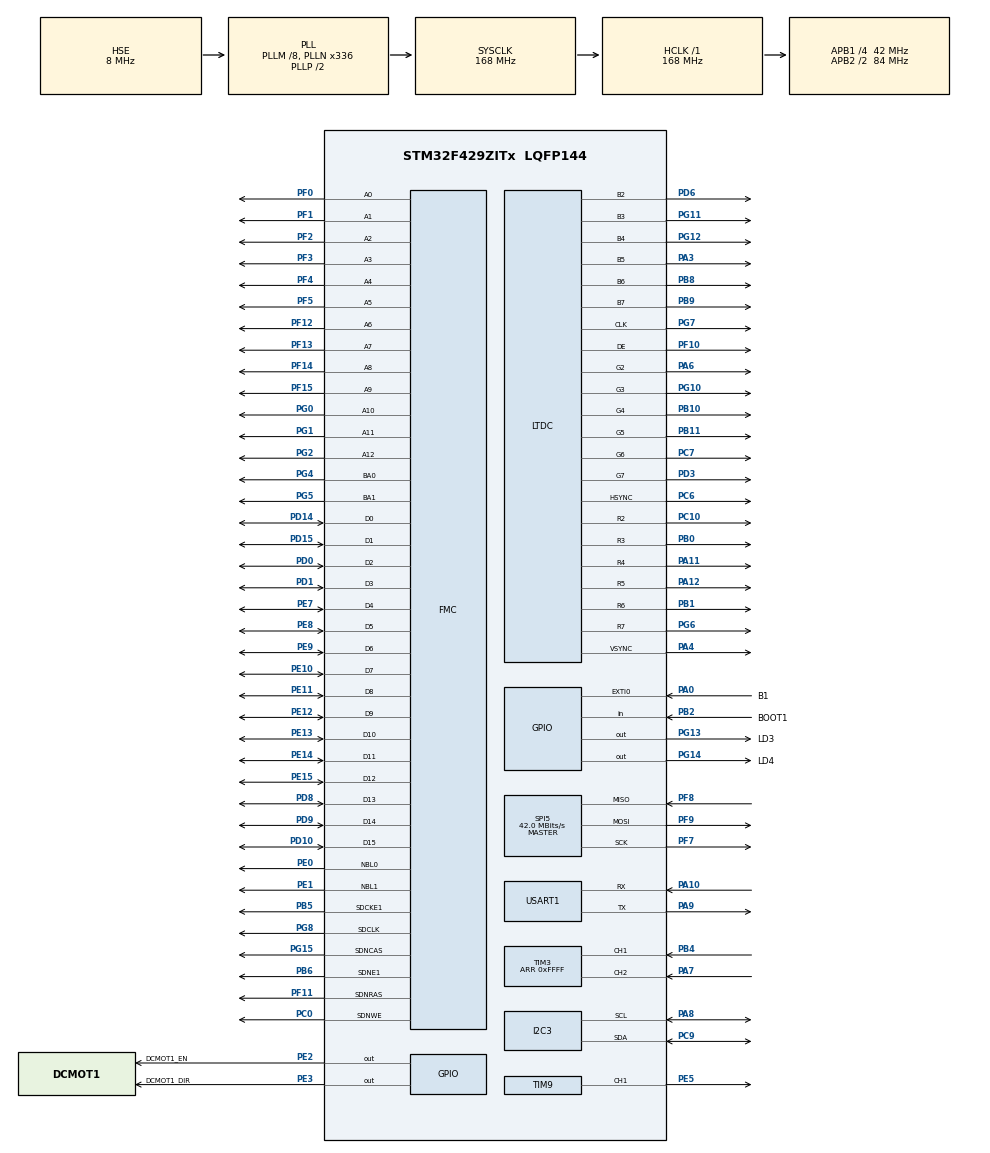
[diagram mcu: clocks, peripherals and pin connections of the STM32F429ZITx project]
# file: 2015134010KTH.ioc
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DMA2D.ColorMode=DMA2D_OUTPUT_RGB565
LTDC.ActiveH=240
LTDC.ActiveW=320
Mcu.Family=STM32F4
Mcu.Name=STM32F429ZITx
Mcu.Package=LQFP144
NVIC.EXTI0_IRQn=true\:0\:0\:false\:true\:true\:1\:true\:true
NVIC.PriorityGroup=NVIC_PRIORITYGROUP_4
NVIC.TIM6_DAC_IRQn=true\:0\:0\:false\:true\:true\:2\:true\:true
PA0/WKUP.GPIO_Label=B1
PA0/WKUP.Signal=GPXTI0
PA10.Mode=Asynchronous
PA10.Signal=USART1_RX
PA11.Mode=RGB666
PA11.Signal=LTDC_R4
PA12.Mode=RGB666
PA12.Signal=LTDC_R5
PA13.Mode=Serial_Wire
PA13.Signal=SYS_JTMS-SWDIO
PA14.Mode=Serial_Wire
PA14.Signal=SYS_JTCK-SWCLK
PA3.Mode=RGB666
PA3.Signal=LTDC_B5
PA4.Mode=RGB666
PA4.Signal=LTDC_VSYNC
PA6.Mode=RGB666
PA6.Signal=LTDC_G2
PA7.GPIO_Speed=GPIO_SPEED_FREQ_VERY_HIGH
PA7.Signal=S_TIM3_CH2
PA8.Mode=I2C
PA8.Signal=I2C3_SCL
PA9.Mode=Asynchronous
PA9.Signal=USART1_TX
PB0.Mode=RGB666
PB0.Signal=LTDC_R3
PB1.Mode=RGB666
PB1.Signal=LTDC_R6
PB10.Mode=RGB666
PB10.Signal=LTDC_G4
PB11.Mode=RGB666
PB11.Signal=LTDC_G5
PB2/BOOT1.GPIO_Label=BOOT1
PB2/BOOT1.Signal=GPIO_Input
PB4.GPIO_Speed=GPIO_SPEED_FREQ_VERY_HIGH
PB4.Signal=S_TIM3_CH1
PB5.Mode=SdramChipSelect2_1
PB5.Signal=FMC_SDCKE1
PB6.Mode=SdramChipSelect2_1
PB6.Signal=FMC_SDNE1
PB8.Mode=RGB666
PB8.Signal=LTDC_B6
PB9.Mode=RGB666
PB9.Signal=LTDC_B7
PC0.Signal=FMC_SDNWE
PC10.Mode=RGB666
PC10.Signal=LTDC_R2
PC6.Mode=RGB666
PC6.Signal=LTDC_HSYNC
PC7.Mode=RGB666
PC7.Signal=LTDC_G6
PC9.Mode=I2C
PC9.Signal=I2C3_SDA
PD0.Signal=FMC_D2_DA2
PD1.Signal=FMC_D3_DA3
PD10.Signal=FMC_D15_DA15
PD14.Signal=FMC_D0_DA0
PD15.Signal=FMC_D1_DA1
PD3.Mode=RGB666
PD3.Signal=LTDC_G7
PD6.Mode=RGB666
PD6.Signal=LTDC_B2
PD8.Signal=FMC_D13_DA13
PD9.Signal=FMC_D14_DA14
PE0.Signal=FMC_NBL0
PE1.Signal=FMC_NBL1
PE10.Signal=FMC_D7_DA7
PE11.Signal=FMC_D8_DA8
PE12.Signal=FMC_D9_DA9
PE13.Signal=FMC_D10_DA10
PE14.Signal=FMC_D11_DA11
PE15.Signal=FMC_D12_DA12
PE2.GPIO_Label=DCMOT1_EN
PE2.GPIO_Speed=GPIO_SPEED_FREQ_VERY_HIGH
PE2.Signal=GPIO_Output
PE3.GPIO_Label=DCMOT1_DIR
PE3.GPIO_Speed=GPIO_SPEED_FREQ_VERY_HIGH
PE3.Signal=GPIO_Output
PE5.GPIO_Speed=GPIO_SPEED_FREQ_VERY_HIGH
PE5.Signal=S_TIM9_CH1
PE7.Signal=FMC_D4_DA4
PE8.Signal=FMC_D5_DA5
PE9.Signal=FMC_D6_DA6
PF0.Signal=FMC_A0
PF1.Signal=FMC_A1
PF10.Mode=RGB666
PF10.Signal=LTDC_DE
PF11.Signal=FMC_SDNRAS
PF12.Signal=FMC_A6
PF13.Signal=FMC_A7
PF14.Signal=FMC_A8
PF15.Signal=FMC_A9
PF2.Signal=FMC_A2
PF3.Signal=FMC_A3
PF4.Signal=FMC_A4
PF5.Signal=FMC_A5
PF7.Mode=Full_Duplex_Master
PF7.Signal=SPI5_SCK
PF8.Mode=Full_Duplex_Master
PF8.Signal=SPI5_MISO
PF9.Mode=Full_Duplex_Master
PF9.Signal=SPI5_MOSI
PG0.Signal=FMC_A10
PG1.Signal=FMC_A11
PG10.Mode=RGB666
PG10.Signal=LTDC_G3
PG11.Mode=RGB666
PG11.Signal=LTDC_B3
PG12.Mode=RGB666
PG12.Signal=LTDC_B4
PG13.GPIO_Label=LD3
PG13.Signal=GPIO_Output
PG14.GPIO_Label=LD4
PG14.Signal=GPIO_Output
PG15.Signal=FMC_SDNCAS
PG2.Signal=FMC_A12
PG4.Signal=FMC_A14_BA0
PG5.Signal=FMC_A15_BA1
PG6.Mode=RGB666
PG6.Signal=LTDC_R7
PG7.Mode=RGB666
PG7.Signal=LTDC_CLK
PG8.Signal=FMC_SDCLK
PH0/OSC_IN.Mode=HSE-External-Oscillator
PH0/OSC_IN.Signal=RCC_OSC_IN
PH1/OSC_OUT.Mode=HSE-External-Oscillator
PH1/OSC_OUT.Signal=RCC_OSC_OUT
ProjectManager.HeapSize=0x200
ProjectManager.StackSize=0x400
ProjectManager.TargetToolchain=EWARM V8
RCC.48MHZClocksFreq_Value=84000000
RCC.AHBFreq_Value=168000000
RCC.APB1CLKDivider=RCC_HCLK_DIV4
RCC.APB1Freq_Value=42000000
RCC.APB1TimFreq_Value=84000000
RCC.APB2CLKDivider=RCC_HCLK_DIV2
RCC.APB2Freq_Value=84000000
RCC.APB2TimFreq_Value=168000000
RCC.CortexFreq_Value=168000000
RCC.HCLKFreq_Value=168000000
RCC.HSE_VALUE=8000000
RCC.HSI_VALUE=16000000
RCC.LSE_VALUE=32768
RCC.PLLM=8
RCC.PLLN=336
RCC.PLLSAIN=432
RCC.PLLSourceVirtual=RCC_PLLSOURCE_HSE
RCC.SYSCLKFreq_VALUE=168000000
RCC.SYSCLKSource=RCC_SYSCLKSOURCE_PLLCLK
RCC.VCOOutputFreq_Value=336000000
SH.FMC_A0.0=FMC_A0,13b-sda1
SH.FMC_A1.0=FMC_A1,13b-sda1
SH.FMC_A10.0=FMC_A10,13b-sda1
SH.FMC_A11.0=FMC_A11,13b-sda1
SH.FMC_A12.0=FMC_A12,13b-sda1
SH.FMC_A14_BA0.0=FMC_BA0,FourSdramBanks1
SH.FMC_A15_BA1.0=FMC_BA1,FourSdramBanks1
SH.FMC_A2.0=FMC_A2,13b-sda1
SH.FMC_A3.0=FMC_A3,13b-sda1
SH.FMC_A4.0=FMC_A4,13b-sda1
SH.FMC_A5.0=FMC_A5,13b-sda1
SH.FMC_A6.0=FMC_A6,13b-sda1
SH.FMC_A7.0=FMC_A7,13b-sda1
SH.FMC_A8.0=FMC_A8,13b-sda1
SH.FMC_A9.0=FMC_A9,13b-sda1
SH.FMC_D0_DA0.0=FMC_D0,sd-16b-d1
SH.FMC_D10_DA10.0=FMC_D10,sd-16b-d1
SH.FMC_D11_DA11.0=FMC_D11,sd-16b-d1
SH.FMC_D12_DA12.0=FMC_D12,sd-16b-d1
SH.FMC_D13_DA13.0=FMC_D13,sd-16b-d1
SH.FMC_D14_DA14.0=FMC_D14,sd-16b-d1
SH.FMC_D15_DA15.0=FMC_D15,sd-16b-d1
SH.FMC_D1_DA1.0=FMC_D1,sd-16b-d1
SH.FMC_D2_DA2.0=FMC_D2,sd-16b-d1
SH.FMC_D3_DA3.0=FMC_D3,sd-16b-d1
SH.FMC_D4_DA4.0=FMC_D4,sd-16b-d1
SH.FMC_D5_DA5.0=FMC_D5,sd-16b-d1
SH.FMC_D6_DA6.0=FMC_D6,sd-16b-d1
SH.FMC_D7_DA7.0=FMC_D7,sd-16b-d1
SH.FMC_D8_DA8.0=FMC_D8,sd-16b-d1
SH.FMC_D9_DA9.0=FMC_D9,sd-16b-d1
SH.FMC_NBL0.0=FMC_NBL0,Sd2ByteEnable1
SH.FMC_NBL1.0=FMC_NBL1,Sd2ByteEnable1
SH.FMC_SDCLK.0=FMC_SDCLK,13b-sda1
SH.FMC_SDNCAS.0=FMC_SDNCAS,13b-sda1
SH.FMC_SDNRAS.0=FMC_SDNRAS,13b-sda1
SH.FMC_SDNWE.0=FMC_SDNWE,13b-sda1
SH.S_TIM3_CH1.0=TIM3_CH1,Encoder_Interface
SH.S_TIM3_CH2.0=TIM3_CH2,Encoder_Interface
SH.S_TIM9_CH1.0=TIM9_CH1,PWM Generation1 CH1
SPI5.CalculateBaudRate=42.0 MBits/s
SPI5.Direction=SPI_DIRECTION_2LINES
SPI5.Mode=SPI_MODE_MASTER
SPI5.VirtualType=VM_MASTER
TIM3.Period=0xFFFF
TIM6.Period=1000-1
TIM6.Prescaler=84-1
TIM9.Channel-PWM\ Generation1\ CH1=TIM_CHANNEL_1
TIM9.Period=100-1
TIM9.Prescaler=84-1
TIM9.Pulse-PWM\ Generation1\ CH1=10
USART1.VirtualMode=VM_ASYNC
VP_CRC_VS_CRC.Mode=CRC_Activate
VP_DMA2D_VS_DMA2D.Mode=DMA2D_Activate
VP_TIM6_VS_ClockSourceINT.Mode=Enable_Timer
VP_TIM9_VS_ClockSourceINT.Mode=Internal
board=custom

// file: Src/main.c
/* USER CODE BEGIN Header */
/**
******************************************************************************
* @file           : main.c
* @brief          : Main program body
******************************************************************************
* @attention
*
* <h2><center>&copy; Copyright (c) 2020 STMicroelectronics.
* All rights reserved.</center></h2>
*
* This software component is licensed by ST under BSD 3-Clause license,
* the "License"; You may not use this file except in compliance with the
* License. You may obtain a copy of the License at:
*                        opensource.org/licenses/BSD-3-Clause
*
******************************************************************************
*/
/* USER CODE END Header */

#include "main.h"

/* USER CODE BEGIN Includes */
#include <stdio.h>
#include <string.h>
#include <math.h>

#include "mathext.h"
#include "DcMotor.h"
#include "DcMotorExtern.h"

#include  "stm32f429i_discovery.h"
#include  "stm32f429i_discovery_lcd.h"
/* USER CODE END Includes */

/* USER CODE BEGIN PD */

#define PID_SUM_TYPE     2
#define PWM_MAX_STEP  10
#define PWM_MIN_POSITIVE        22
#define PWM_MIN_NEGATIVE       -22

/* USER CODE END PD */

CRC_HandleTypeDef hcrc;

DMA2D_HandleTypeDef hdma2d;

I2C_HandleTypeDef hi2c3;

LTDC_HandleTypeDef hltdc;

SPI_HandleTypeDef hspi5;

TIM_HandleTypeDef htim3;
TIM_HandleTypeDef htim6;
TIM_HandleTypeDef htim9;

UART_HandleTypeDef huart1;

SDRAM_HandleTypeDef hsdram1;

/* USER CODE BEGIN PV */

//형 선언
typedef enum _bool
{
  FALSE=0,
  TRUE=1
} bool;
bool a =TRUE;

struct
{
  float Kp;
  float Ki;
  float Kd;
} PidParam={0.97,0.0042, 0.015};

enum {
  STATE_IDLE = 0,
  STATE_RUN_SAVE,
  STATE_NORUN_PRINT,
  STATE_RUN_ONLY,
} RunState={STATE_RUN_SAVE};

bool flagTim4=FALSE;
int16_t flagUser=0;

int LcdMaxX, LcdMaxY;
int posX, posY;

int y=10,count=0;
int map_X;

/* USER CODE END PV */

void SystemClock_Config(void);
static void MX_GPIO_Init(void);
static void MX_USART1_UART_Init(void);
static void MX_TIM9_Init(void);
static void MX_TIM6_Init(void);
static void MX_DMA2D_Init(void);
static void MX_FMC_Init(void);
static void MX_I2C3_Init(void);
static void MX_SPI5_Init(void);
static void MX_LTDC_Init(void);
static void MX_TIM3_Init(void);
static void MX_CRC_Init(void);
static void MX_NVIC_Init(void);
/* USER CODE BEGIN PFP */

void screen();
void Displayscreen();
/* USER CODE END PFP */

/* USER CODE BEGIN 0 */

void  ReadEncoder() // 엔코더 값 32비트 만들기
{
  //엔코더 위치 및 샘플링당 엔코더차이(속도) 16bit 계산
  DcMotor1.Encoder16 = DcMotor1ReadEncoder();//TIM4 16비트
  //인터럽트간 엔코더값 차이 계산 => 실제의미는 속도
  DcMotor1.Encoder16Diff= DcMotor1.Encoder16- DcMotor1.Encoder16Old;
  DcMotor1.Encoder16Old = DcMotor1.Encoder16;

  //엔코더 위치 및 샘플링당 엔코더차이(속도) 32bit 로 확장
  // TIM3는 16CNT , 모터 8회전하면 오버플로우문제가 발생
  // 현재위치 = 누적합 of 인터럽트간 엔코더값의 변화
  //x DcMotor1.Encoder32 = DcMotor1.Encoder16;
  DcMotor1.Encoder32 += DcMotor1.Encoder16Diff;
  DcMotor1.Encoder32Diff = DcMotor1.Encoder32- DcMotor1.Encoder32Old;//=DcMotor1.Encoder16Diff
  DcMotor1.Encoder32Old = DcMotor1.Encoder32;

  Controller1.Output32 = DcMotor1.Encoder32;
}

void PidControlInit() // 초기화 설정
{
  // DC Motor 관련변수 초기화
  DcMotor1.Encoder16Old = 0;
  DcMotor1.Encoder32 = 0 ;
  DcMotor1.Encoder32Old = 0 ;
  DcMotor1.Encoder32Diff = 0;

  // 제어기 관련변수 초기화
  Controller1.Output32 = DcMotor1.Encoder32;
  Controller1.Target32 = WHEEL_RESOLUTION; //4096으로 설정 했었음.
  Controller1.ErrorOld32 = 0;
  Controller1.ErrorSum32 =0;
  Controller1.loop =0;

  //PWM duty =0
  DcMotor1SetDutyPulse(&htim9, 0);

  //htim4->CNT <= 0x0000 (16bit 카운터 clear)
  __HAL_TIM_SET_COUNTER(&htim3,   0x0000);
}

float TermKp,TermKi,TermKd;

void PidControl()
{
  // 목표값과 현재 플랜트 출력의 오차
  Controller1.Error32 = Controller1.Target32- Controller1.Output32;  // 4096 - 현재 pid값
  //   Controller1.ErrorSum32 += Controller1.Error32; //오차의 합(적분값)
  //   Controller1.ErrorSum32 += (Controller1.Error32+Controller1.ErrorOld32)/2; //오차의 합(적분값)

#ifdef PID_SUM_TYPE
  //Euler 적분
  Controller1.ErrorSum32 += Controller1.Error32; //오차의 합(적분값) // error 값 다 더하기.
#else
  //사다리꼴 적분
  Controller1.ErrorSum32 += (Controller1.Error32+Controller1.ErrorOld32)/2; //오차의 합(적분값)
#endif

  Controller1.ErrorDiff32 = Controller1.Error32- Controller1.ErrorOld32; // 샘플간 오차의 차이(미분값)
  Controller1.ErrorOld32 = Controller1.Error32;

  //ErrorSum 최대값 제한
#define ERRROR_SUM_MAX  (WHEEL_RESOLUTION*0.5)
  //  Controller1.ErrorSum32 = LimitFloat(Controller1.ErrorSum32 , ERRROR_SUM_MAX);
#undef ERRROR_SUM_MAX

  TermKp =  PidParam.Kp * Controller1.Error32 ; //비례제어값
  TermKi = PidParam.Ki * Controller1.ErrorSum32 * Tsample; //적분제어값
  TermKd =  PidParam.Kd * Controller1.ErrorDiff32 / Tsample ;//미분제어값
  Controller1.f = TermKp + TermKi + TermKd;

  //PWM pulse 실수=>+-100이내의 정수값 변환
  Controller1.U = FloatToInt16Limit( Controller1.f ,  U_MAX);
  //PWM dead zone 피하기
  Controller1.U  = AvoidDeadzone(Controller1.U, PWM_MIN_POSITIVE,  PWM_MIN_NEGATIVE);
  //PWM pulse 폭 설정
  DcMotor1SetDutyPulse(&htim9, Controller1.U);
}

void PidControlRecord()
{
  Backup1.RecordOutput[Controller1.loop]= Controller1.Output32;
  Backup1.RecordU[Controller1.loop] = Controller1.U;
  Backup1.RecordError[Controller1.loop] = Controller1.Error32;
  Backup1.RecordErrorSum[Controller1.loop] = Controller1.ErrorSum32;
  Backup1.RecordErrorDiff[Controller1.loop] = Controller1.ErrorDiff32;
}

void PidControlResultTransmit()
{
  char string[200];
  HAL_UART_Transmit(&huart1, (uint8_t *)"Record Print\r\n", strlen("Record Print\r\n"), 1000);
  for(int i=0 ; i<RECORD_MAX ; i++ )
  {
    sprintf(string, "%7d %5d %6d \r\n", i, Backup1.RecordOutput[i], Backup1.RecordU[i]);
    HAL_UART_Transmit( &huart1, (uint8_t *)string, strlen(string), 1000);
  }
}
void screen()
{
  BSP_LCD_DisplayChar(100,310, Controller1.Output32/1000+0x30);
  BSP_LCD_DisplayChar(110,310, Controller1.Output32%1000/100+0x30);
  BSP_LCD_DisplayChar(120,310, Controller1.Output32%100/10+0x30);
  BSP_LCD_DisplayChar(130,310, Controller1.Output32%10+0x30);
}

void Displayscreen()
{
  BSP_LCD_Init();
  BSP_LCD_LayerDefaultInit(LCD_BACKGROUND_LAYER, LCD_FRAME_BUFFER);
  BSP_LCD_LayerDefaultInit(LCD_FOREGROUND_LAYER, LCD_FRAME_BUFFER);

  BSP_LCD_SelectLayer(LCD_FOREGROUND_LAYER);

  BSP_LCD_SetBackColor(LCD_COLOR_BLACK);

  BSP_LCD_Clear(LCD_COLOR_BLACK);

  BSP_LCD_SetTextColor(LCD_COLOR_WHITE);
  LcdMaxX = BSP_LCD_GetXSize();
  LcdMaxY = BSP_LCD_GetYSize();

  BSP_LCD_DrawRect(10,10,200,300);

  BSP_LCD_SetTextColor(LCD_COLOR_GREEN);

  BSP_LCD_DrawLine(210*4096/5000,10,210*4096/5000,310);
}

long map(long x, long in_min, long in_max, long out_min, long out_max)
{
  return (x - in_min) * (out_max - out_min) / (in_max - in_min) + out_min;
}
/* USER CODE END 0 */

int main(void)
{

  /* MCU Configuration--------------------------------------------------------*/

  /* Reset of all peripherals, Initializes the Flash interface and the Systick. */
  HAL_Init();

  /* Configure the system clock */
  SystemClock_Config();

  /* Initialize all configured peripherals */
  MX_GPIO_Init();
  MX_USART1_UART_Init();
  MX_TIM9_Init();
  MX_TIM6_Init();
  MX_DMA2D_Init();
  MX_FMC_Init();
  MX_I2C3_Init();
  MX_SPI5_Init();
  MX_LTDC_Init();
  MX_TIM3_Init();
  MX_CRC_Init();

  /* Initialize interrupts */
  MX_NVIC_Init();
  /* USER CODE BEGIN 2 */
  Displayscreen();
  BSP_LCD_SetFont(&Font16);
  PidControlInit();
  HAL_TIM_Encoder_Start(&htim3, TIM_CHANNEL_1 | TIM_CHANNEL_2 );
  HAL_TIM_Base_Start_IT(&htim6);
  HAL_TIM_PWM_Start(&htim9, TIM_CHANNEL_1);

  /* USER CODE END 2 */

  /* Infinite loop */
  while (1)
  {

    /* USER CODE BEGIN 3 */
    map_X= map(Controller1.Output32,0,5000,10,210);

    if(flagUser==1)
    {
      DcMotor1Disable();
      PidControlResultTransmit();
      PidControlInit();
      DcMotor1Enable();

      BSP_LCD_Clear(LCD_COLOR_BLACK);
      BSP_LCD_SetTextColor(LCD_COLOR_WHITE);
      BSP_LCD_DrawRect(10,10,200,300);

      BSP_LCD_SetTextColor(LCD_COLOR_GREEN);
      BSP_LCD_DrawLine(210*4096/5000,10,210*4096/5000,310);

      RunState=STATE_RUN_SAVE;

      flagUser=0;
    }
    screen();

    if(flagTim4==TRUE)
    {

      ReadEncoder();

      switch(RunState)
      {
      case STATE_RUN_SAVE:
        if(Controller1.loop< RECORD_MAX)
        {
          PidControl();

          PidControlRecord();

          Controller1.loop++;

          BSP_LCD_DrawPixel(map_X,Controller1.loop+10,LCD_COLOR_YELLOW);
        }
        else
        {
          Controller1.loop = 0;
          RunState = STATE_RUN_ONLY;
        }
        break;

      case STATE_NORUN_PRINT:
        //TIM6 interrupt disable
        HAL_NVIC_DisableIRQ( TIM6_DAC_IRQn);
        DcMotor1SetDutyPulse(&htim9, 0);
        PidControlResultTransmit();
        Controller1.loop = 0;
        //TIM6 interrupt enable
        HAL_NVIC_EnableIRQ( TIM6_DAC_IRQn);
        break;

      case STATE_RUN_ONLY:
        PidControl();

        break;

      case STATE_IDLE:
        break;
      }
      flagTim4=FALSE;
    }
  }
  /* USER CODE END 3 */
}

void SystemClock_Config(void)
{
  RCC_OscInitTypeDef RCC_OscInitStruct = {0};
  RCC_ClkInitTypeDef RCC_ClkInitStruct = {0};
  RCC_PeriphCLKInitTypeDef PeriphClkInitStruct = {0};

  /** Configure the main internal regulator output voltage
  */
  __HAL_RCC_PWR_CLK_ENABLE();
  __HAL_PWR_VOLTAGESCALING_CONFIG(PWR_REGULATOR_VOLTAGE_SCALE1);
  /** Initializes the CPU, AHB and APB busses clocks
  */
  RCC_OscInitStruct.OscillatorType = RCC_OSCILLATORTYPE_HSE;
  RCC_OscInitStruct.HSEState = RCC_HSE_ON;
  RCC_OscInitStruct.PLL.PLLState = RCC_PLL_ON;
  RCC_OscInitStruct.PLL.PLLSource = RCC_PLLSOURCE_HSE;
  RCC_OscInitStruct.PLL.PLLM = 8;
  RCC_OscInitStruct.PLL.PLLN = 336;
  RCC_OscInitStruct.PLL.PLLP = RCC_PLLP_DIV2;
  RCC_OscInitStruct.PLL.PLLQ = 4;
  if (HAL_RCC_OscConfig(&RCC_OscInitStruct) != HAL_OK)
  {
    Error_Handler();
  }
  /** Initializes the CPU, AHB and APB busses clocks
  */
  RCC_ClkInitStruct.ClockType = RCC_CLOCKTYPE_HCLK|RCC_CLOCKTYPE_SYSCLK
    |RCC_CLOCKTYPE_PCLK1|RCC_CLOCKTYPE_PCLK2;
  RCC_ClkInitStruct.SYSCLKSource = RCC_SYSCLKSOURCE_PLLCLK;
  RCC_ClkInitStruct.AHBCLKDivider = RCC_SYSCLK_DIV1;
  RCC_ClkInitStruct.APB1CLKDivider = RCC_HCLK_DIV4;
  RCC_ClkInitStruct.APB2CLKDivider = RCC_HCLK_DIV2;

  if (HAL_RCC_ClockConfig(&RCC_ClkInitStruct, FLASH_LATENCY_5) != HAL_OK)
  {
    Error_Handler();
  }
  PeriphClkInitStruct.PeriphClockSelection = RCC_PERIPHCLK_LTDC;
  PeriphClkInitStruct.PLLSAI.PLLSAIN = 432;
  PeriphClkInitStruct.PLLSAI.PLLSAIR = 2;
  PeriphClkInitStruct.PLLSAIDivR = RCC_PLLSAIDIVR_2;
  if (HAL_RCCEx_PeriphCLKConfig(&PeriphClkInitStruct) != HAL_OK)
  {
    Error_Handler();
  }
}

/**
* @brief NVIC Configuration.
* @retval None
*/
static void MX_NVIC_Init(void)
{
  /* EXTI0_IRQn interrupt configuration */
  HAL_NVIC_SetPriority(EXTI0_IRQn, 0, 0);
  HAL_NVIC_EnableIRQ(EXTI0_IRQn);
  /* TIM6_DAC_IRQn interrupt configuration */
  HAL_NVIC_SetPriority(TIM6_DAC_IRQn, 0, 0);
  HAL_NVIC_EnableIRQ(TIM6_DAC_IRQn);
}

static void MX_CRC_Init(void)
{

  hcrc.Instance = CRC;
  if (HAL_CRC_Init(&hcrc) != HAL_OK)
  {
    Error_Handler();
  }

}

static void MX_DMA2D_Init(void)
{

  hdma2d.Instance = DMA2D;
  hdma2d.Init.Mode = DMA2D_M2M;
  hdma2d.Init.ColorMode = DMA2D_OUTPUT_RGB565;
  hdma2d.Init.OutputOffset = 0;
  hdma2d.LayerCfg[1].InputOffset = 0;
  hdma2d.LayerCfg[1].InputColorMode = DMA2D_INPUT_RGB565;
  hdma2d.LayerCfg[1].AlphaMode = DMA2D_NO_MODIF_ALPHA;
  hdma2d.LayerCfg[1].InputAlpha = 0;
  if (HAL_DMA2D_Init(&hdma2d) != HAL_OK)
  {
    Error_Handler();
  }
  if (HAL_DMA2D_ConfigLayer(&hdma2d, 1) != HAL_OK)
  {
    Error_Handler();
  }

}

static void MX_I2C3_Init(void)
{

  hi2c3.Instance = I2C3;
  hi2c3.Init.ClockSpeed = 100000;
  hi2c3.Init.DutyCycle = I2C_DUTYCYCLE_2;
  hi2c3.Init.OwnAddress1 = 0;
  hi2c3.Init.AddressingMode = I2C_ADDRESSINGMODE_7BIT;
  hi2c3.Init.DualAddressMode = I2C_DUALADDRESS_DISABLE;
  hi2c3.Init.OwnAddress2 = 0;
  hi2c3.Init.GeneralCallMode = I2C_GENERALCALL_DISABLE;
  hi2c3.Init.NoStretchMode = I2C_NOSTRETCH_DISABLE;
  if (HAL_I2C_Init(&hi2c3) != HAL_OK)
  {
    Error_Handler();
  }
  /** Configure Analogue filter
  */
  if (HAL_I2CEx_ConfigAnalogFilter(&hi2c3, I2C_ANALOGFILTER_ENABLE) != HAL_OK)
  {
    Error_Handler();
  }
  /** Configure Digital filter
  */
  if (HAL_I2CEx_ConfigDigitalFilter(&hi2c3, 0) != HAL_OK)
  {
    Error_Handler();
  }

}

static void MX_LTDC_Init(void)
{

  LTDC_LayerCfgTypeDef pLayerCfg = {0};
  LTDC_LayerCfgTypeDef pLayerCfg1 = {0};

  hltdc.Instance = LTDC;
  hltdc.Init.HSPolarity = LTDC_HSPOLARITY_AL;
  hltdc.Init.VSPolarity = LTDC_VSPOLARITY_AL;
  hltdc.Init.DEPolarity = LTDC_DEPOLARITY_AL;
  hltdc.Init.PCPolarity = LTDC_PCPOLARITY_IPC;
  hltdc.Init.HorizontalSync = 7;
  hltdc.Init.VerticalSync = 3;
  hltdc.Init.AccumulatedHBP = 14;
  hltdc.Init.AccumulatedVBP = 5;
  hltdc.Init.AccumulatedActiveW = 334;
  hltdc.Init.AccumulatedActiveH = 245;
  hltdc.Init.TotalWidth = 340;
  hltdc.Init.TotalHeigh = 247;
  hltdc.Init.Backcolor.Blue = 0;
  hltdc.Init.Backcolor.Green = 0;
  hltdc.Init.Backcolor.Red = 0;
  if (HAL_LTDC_Init(&hltdc) != HAL_OK)
  {
    Error_Handler();
  }
  pLayerCfg.WindowX0 = 0;
  pLayerCfg.WindowX1 = 0;
  pLayerCfg.WindowY0 = 0;
  pLayerCfg.WindowY1 = 0;
  pLayerCfg.PixelFormat = LTDC_PIXEL_FORMAT_ARGB8888;
  pLayerCfg.Alpha = 0;
  pLayerCfg.Alpha0 = 0;
  pLayerCfg.BlendingFactor1 = LTDC_BLENDING_FACTOR1_CA;
  pLayerCfg.BlendingFactor2 = LTDC_BLENDING_FACTOR2_CA;
  pLayerCfg.FBStartAdress = 0;
  pLayerCfg.ImageWidth = 0;
  pLayerCfg.ImageHeight = 0;
  pLayerCfg.Backcolor.Blue = 0;
  pLayerCfg.Backcolor.Green = 0;
  pLayerCfg.Backcolor.Red = 0;
  if (HAL_LTDC_ConfigLayer(&hltdc, &pLayerCfg, 0) != HAL_OK)
  {
    Error_Handler();
  }
  pLayerCfg1.WindowX0 = 0;
  pLayerCfg1.WindowX1 = 0;
  pLayerCfg1.WindowY0 = 0;
  pLayerCfg1.WindowY1 = 0;
  pLayerCfg1.PixelFormat = LTDC_PIXEL_FORMAT_ARGB8888;
  pLayerCfg1.Alpha = 0;
  pLayerCfg1.Alpha0 = 0;
  pLayerCfg1.BlendingFactor1 = LTDC_BLENDING_FACTOR1_CA;
  pLayerCfg1.BlendingFactor2 = LTDC_BLENDING_FACTOR2_CA;
  pLayerCfg1.FBStartAdress = 0;
  pLayerCfg1.ImageWidth = 0;
  pLayerCfg1.ImageHeight = 0;
  pLayerCfg1.Backcolor.Blue = 0;
  pLayerCfg1.Backcolor.Green = 0;
  pLayerCfg1.Backcolor.Red = 0;
  if (HAL_LTDC_ConfigLayer(&hltdc, &pLayerCfg1, 1) != HAL_OK)
  {
    Error_Handler();
  }

}

static void MX_SPI5_Init(void)
{

  /* SPI5 parameter configuration*/
  hspi5.Instance = SPI5;
  hspi5.Init.Mode = SPI_MODE_MASTER;
  hspi5.Init.Direction = SPI_DIRECTION_2LINES;
  hspi5.Init.DataSize = SPI_DATASIZE_8BIT;
  hspi5.Init.CLKPolarity = SPI_POLARITY_LOW;
  hspi5.Init.CLKPhase = SPI_PHASE_1EDGE;
  hspi5.Init.NSS = SPI_NSS_SOFT;
  hspi5.Init.BaudRatePrescaler = SPI_BAUDRATEPRESCALER_2;
  hspi5.Init.FirstBit = SPI_FIRSTBIT_MSB;
  hspi5.Init.TIMode = SPI_TIMODE_DISABLE;
  hspi5.Init.CRCCalculation = SPI_CRCCALCULATION_DISABLE;
  hspi5.Init.CRCPolynomial = 10;
  if (HAL_SPI_Init(&hspi5) != HAL_OK)
  {
    Error_Handler();
  }

}

static void MX_TIM3_Init(void)
{

  TIM_Encoder_InitTypeDef sConfig = {0};
  TIM_MasterConfigTypeDef sMasterConfig = {0};

  htim3.Instance = TIM3;
  htim3.Init.Prescaler = 0;
  htim3.Init.CounterMode = TIM_COUNTERMODE_UP;
  htim3.Init.Period = 0xFFFF;
  htim3.Init.ClockDivision = TIM_CLOCKDIVISION_DIV1;
  htim3.Init.AutoReloadPreload = TIM_AUTORELOAD_PRELOAD_DISABLE;
  sConfig.EncoderMode = TIM_ENCODERMODE_TI1;
  sConfig.IC1Polarity = TIM_ICPOLARITY_RISING;
  sConfig.IC1Selection = TIM_ICSELECTION_DIRECTTI;
  sConfig.IC1Prescaler = TIM_ICPSC_DIV1;
  sConfig.IC1Filter = 0;
  sConfig.IC2Polarity = TIM_ICPOLARITY_RISING;
  sConfig.IC2Selection = TIM_ICSELECTION_DIRECTTI;
  sConfig.IC2Prescaler = TIM_ICPSC_DIV1;
  sConfig.IC2Filter = 0;
  if (HAL_TIM_Encoder_Init(&htim3, &sConfig) != HAL_OK)
  {
    Error_Handler();
  }
  sMasterConfig.MasterOutputTrigger = TIM_TRGO_RESET;
  sMasterConfig.MasterSlaveMode = TIM_MASTERSLAVEMODE_DISABLE;
  if (HAL_TIMEx_MasterConfigSynchronization(&htim3, &sMasterConfig) != HAL_OK)
  {
    Error_Handler();
  }

}

static void MX_TIM6_Init(void)
{

  TIM_MasterConfigTypeDef sMasterConfig = {0};

  htim6.Instance = TIM6;
  htim6.Init.Prescaler = 84-1;
  htim6.Init.CounterMode = TIM_COUNTERMODE_UP;
  htim6.Init.Period = 1000-1;
  htim6.Init.AutoReloadPreload = TIM_AUTORELOAD_PRELOAD_DISABLE;
  if (HAL_TIM_Base_Init(&htim6) != HAL_OK)
  {
    Error_Handler();
  }
  sMasterConfig.MasterOutputTrigger = TIM_TRGO_RESET;
  sMasterConfig.MasterSlaveMode = TIM_MASTERSLAVEMODE_DISABLE;
  if (HAL_TIMEx_MasterConfigSynchronization(&htim6, &sMasterConfig) != HAL_OK)
  {
    Error_Handler();
  }

}

static void MX_TIM9_Init(void)
{

  TIM_ClockConfigTypeDef sClockSourceConfig = {0};
  TIM_OC_InitTypeDef sConfigOC = {0};

  htim9.Instance = TIM9;
  htim9.Init.Prescaler = 84-1;
  htim9.Init.CounterMode = TIM_COUNTERMODE_UP;
  htim9.Init.Period = 100-1;
  htim9.Init.ClockDivision = TIM_CLOCKDIVISION_DIV1;
  htim9.Init.AutoReloadPreload = TIM_AUTORELOAD_PRELOAD_DISABLE;
  if (HAL_TIM_Base_Init(&htim9) != HAL_OK)
  {
    Error_Handler();
  }
  sClockSourceConfig.ClockSource = TIM_CLOCKSOURCE_INTERNAL;
  if (HAL_TIM_ConfigClockSource(&htim9, &sClockSourceConfig) != HAL_OK)
  {
    Error_Handler();
  }
  if (HAL_TIM_PWM_Init(&htim9) != HAL_OK)
  {
    Error_Handler();
  }
  sConfigOC.OCMode = TIM_OCMODE_PWM1;
  sConfigOC.Pulse = 10;
  sConfigOC.OCPolarity = TIM_OCPOLARITY_HIGH;
  sConfigOC.OCFastMode = TIM_OCFAST_DISABLE;
  if (HAL_TIM_PWM_ConfigChannel(&htim9, &sConfigOC, TIM_CHANNEL_1) != HAL_OK)
  {
    Error_Handler();
  }
  HAL_TIM_MspPostInit(&htim9);

}

static void MX_USART1_UART_Init(void)
{

  huart1.Instance = USART1;
  huart1.Init.BaudRate = 115200;
  huart1.Init.WordLength = UART_WORDLENGTH_8B;
  huart1.Init.StopBits = UART_STOPBITS_1;
  huart1.Init.Parity = UART_PARITY_NONE;
  huart1.Init.Mode = UART_MODE_TX_RX;
  huart1.Init.HwFlowCtl = UART_HWCONTROL_NONE;
  huart1.Init.OverSampling = UART_OVERSAMPLING_16;
  if (HAL_UART_Init(&huart1) != HAL_OK)
  {
    Error_Handler();
  }

}

/* FMC initialization function */
static void MX_FMC_Init(void)
{

  FMC_SDRAM_TimingTypeDef SdramTiming = {0};

  /** Perform the SDRAM1 memory initialization sequence
  */
  hsdram1.Instance = FMC_SDRAM_DEVICE;
  /* hsdram1.Init */
  hsdram1.Init.SDBank = FMC_SDRAM_BANK2;
  hsdram1.Init.ColumnBitsNumber = FMC_SDRAM_COLUMN_BITS_NUM_8;
  hsdram1.Init.RowBitsNumber = FMC_SDRAM_ROW_BITS_NUM_13;
  hsdram1.Init.MemoryDataWidth = FMC_SDRAM_MEM_BUS_WIDTH_16;
  hsdram1.Init.InternalBankNumber = FMC_SDRAM_INTERN_BANKS_NUM_4;
  hsdram1.Init.CASLatency = FMC_SDRAM_CAS_LATENCY_1;
  hsdram1.Init.WriteProtection = FMC_SDRAM_WRITE_PROTECTION_DISABLE;
  hsdram1.Init.SDClockPeriod = FMC_SDRAM_CLOCK_DISABLE;
  hsdram1.Init.ReadBurst = FMC_SDRAM_RBURST_DISABLE;
  hsdram1.Init.ReadPipeDelay = FMC_SDRAM_RPIPE_DELAY_0;
  /* SdramTiming */
  SdramTiming.LoadToActiveDelay = 16;
  SdramTiming.ExitSelfRefreshDelay = 16;
  SdramTiming.SelfRefreshTime = 16;
  SdramTiming.RowCycleDelay = 16;
  SdramTiming.WriteRecoveryTime = 16;
  SdramTiming.RPDelay = 16;
  SdramTiming.RCDDelay = 16;

  if (HAL_SDRAM_Init(&hsdram1, &SdramTiming) != HAL_OK)
  {
    Error_Handler( );
  }

}

static void MX_GPIO_Init(void)
{
  GPIO_InitTypeDef GPIO_InitStruct = {0};

  /* GPIO Ports Clock Enable */
  __HAL_RCC_GPIOE_CLK_ENABLE();
  __HAL_RCC_GPIOF_CLK_ENABLE();
  __HAL_RCC_GPIOH_CLK_ENABLE();
  __HAL_RCC_GPIOC_CLK_ENABLE();
  __HAL_RCC_GPIOA_CLK_ENABLE();
  __HAL_RCC_GPIOB_CLK_ENABLE();
  __HAL_RCC_GPIOG_CLK_ENABLE();
  __HAL_RCC_GPIOD_CLK_ENABLE();

  /*Configure GPIO pin Output Level */
  HAL_GPIO_WritePin(GPIOE, DCMOT1_EN_Pin|DCMOT1_DIR_Pin, GPIO_PIN_RESET);

  /*Configure GPIO pin Output Level */
  HAL_GPIO_WritePin(GPIOG, LD3_Pin|LD4_Pin, GPIO_PIN_RESET);

  /*Configure GPIO pins : DCMOT1_EN_Pin DCMOT1_DIR_Pin */
  GPIO_InitStruct.Pin = DCMOT1_EN_Pin|DCMOT1_DIR_Pin;
  GPIO_InitStruct.Mode = GPIO_MODE_OUTPUT_PP;
  GPIO_InitStruct.Pull = GPIO_NOPULL;
  GPIO_InitStruct.Speed = GPIO_SPEED_FREQ_VERY_HIGH;
  HAL_GPIO_Init(GPIOE, &GPIO_InitStruct);

  /*Configure GPIO pin : B1_Pin */
  GPIO_InitStruct.Pin = B1_Pin;
  GPIO_InitStruct.Mode = GPIO_MODE_IT_RISING;
  GPIO_InitStruct.Pull = GPIO_NOPULL;
  HAL_GPIO_Init(B1_GPIO_Port, &GPIO_InitStruct);

  /*Configure GPIO pin : BOOT1_Pin */
  GPIO_InitStruct.Pin = BOOT1_Pin;
  GPIO_InitStruct.Mode = GPIO_MODE_INPUT;
  GPIO_InitStruct.Pull = GPIO_NOPULL;
  HAL_GPIO_Init(BOOT1_GPIO_Port, &GPIO_InitStruct);

  /*Configure GPIO pins : LD3_Pin LD4_Pin */
  GPIO_InitStruct.Pin = LD3_Pin|LD4_Pin;
  GPIO_InitStruct.Mode = GPIO_MODE_OUTPUT_PP;
  GPIO_InitStruct.Pull = GPIO_NOPULL;
  GPIO_InitStruct.Speed = GPIO_SPEED_FREQ_LOW;
  HAL_GPIO_Init(GPIOG, &GPIO_InitStruct);

}

/* USER CODE BEGIN 4 */

void HAL_GPIO_EXTI_Callback(uint16_t GPIO_Pin)
{
  if(GPIO_Pin== GPIO_PIN_0)
  {
    flagUser =1;
  }
}

void HAL_TIM_PeriodElapsedCallback(TIM_HandleTypeDef *htim)
{
  if( htim->Instance == TIM6)
    HAL_GPIO_TogglePin(LD3_GPIO_Port,  LD3_Pin);
  flagTim4 = TRUE;

  ReadEncoder();
}

/* USER CODE END 4 */

void Error_Handler(void)
{
}

/************************ (C) COPYRIGHT STMicroelectronics *****END OF FILE****/
